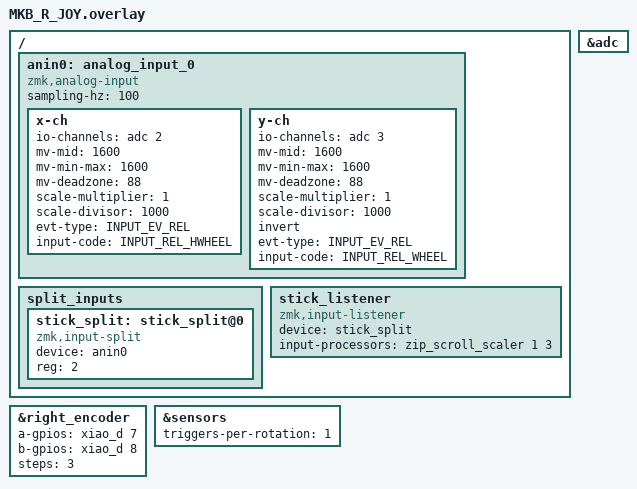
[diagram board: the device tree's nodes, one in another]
#include <zephyr/dt-bindings/input/input-event-codes.h>
#include <input/processors.dtsi>
#include <dt-bindings/zmk/input_transform.h>
#include <dt-bindings/zmk/keys.h>

&adc {
	status = "okay";
};

&right_encoder{
    a-gpios = <&xiao_d 7 (GPIO_ACTIVE_HIGH | GPIO_PULL_UP)>;
    b-gpios = <&xiao_d 8 (GPIO_ACTIVE_HIGH | GPIO_PULL_UP)>;
    steps = <3>;
    status = "okay";
};

&sensors {
    triggers-per-rotation = <1>;
};


/ {
    anin0: analog_input_0 {
        compatible = "zmk,analog-input";
        sampling-hz = <100>;
        x-ch {
            io-channels = <&adc 2>;
            mv-mid = <1600>;
            mv-min-max = <1600>;
            mv-deadzone = <88>;
            scale-multiplier = <1>; //変えない Def 1
            scale-divisor = <1000>; //速度設定　小さくすると速くなる
            //invert; //操作方向反転
            evt-type = <INPUT_EV_REL>;
            //input-code = <INPUT_REL_X>; // マウスで使うときON
            input-code = <INPUT_REL_HWHEEL>; // ホイールで使うときON

        };
        y-ch {
            io-channels = <&adc 3>;
            mv-mid = <1600>;
            mv-min-max = <1600>;
            mv-deadzone = <88>;
            scale-multiplier = <1>; //変えない Def 1
            scale-divisor = <1000>; //速度設定　小さくすると速くなる
            invert; //操作方向反転
            evt-type = <INPUT_EV_REL>;
            //input-code = <INPUT_REL_Y>; //original
            input-code = <INPUT_REL_WHEEL>;
        };
    };

    split_inputs {
        #address-cells = <1>;
        #size-cells = <0>;

        stick_split: stick_split@0 {
            compatible = "zmk,input-split";
            status = "okay";
            device = <&anin0>;
            reg = <2>;
        };
    };
/*
    //Yのみスクロール設定
    input_processors {
        joy_y_to_scroll_mapper: joy_y_to_scroll_mapper {
            compatible = "zmk,input-processor-code-mapper";
            #input-processor-cells = <0>;
            type = <INPUT_EV_REL>;
            map = <INPUT_REL_Y INPUT_REL_WHEEL>;
        };
    };
*/


    stick_listener: stick_listener {
        compatible = "zmk,input-listener";
        status = "okay";
        device = <&stick_split>;
        //マウスカーソル設定
        //input-processors = <&mouse_runtime_input_processor>;

        //上下左右をスクロールするなら下記
        //input-processors = <&zip_xy_to_scroll_mapper &zip_scroll_scaler 1 3>;

        //上下だけをスクロール
        //input-processors = <&joy_y_to_scroll_mapper>;

        //input-processors = <&zip_x_scaler 1 4>, <&zip_scroll_scaler 1 3>;
        input-processors = <&zip_scroll_scaler 1 3>;

    };
};
